# HT32F52243_53 register map
File version: 1.0
This is the description for the Holtek HT32F52243_53
CPU: CM0+ r0p1, little endian, no MPU, no FPU, 4 interrupt priority bits
Registers are 32-bit, read-write, reset 0x0 unless marked. A register's access mark holds for its fields unless they carry their own. Offsets are from the block's base; lines under a group give offsets from that group; [hi:lo] are bit positions; {n}, {i} and the like mark numbered series; 'fields as' and 'values as' point back to an identical list; <NAME> marks a mode.

## Memory map
0xE000E000 NVIC size 0x1000

## NVIC
Base 0xE000E000
0x04 ICTR
  [4:0] INTLINESNUM
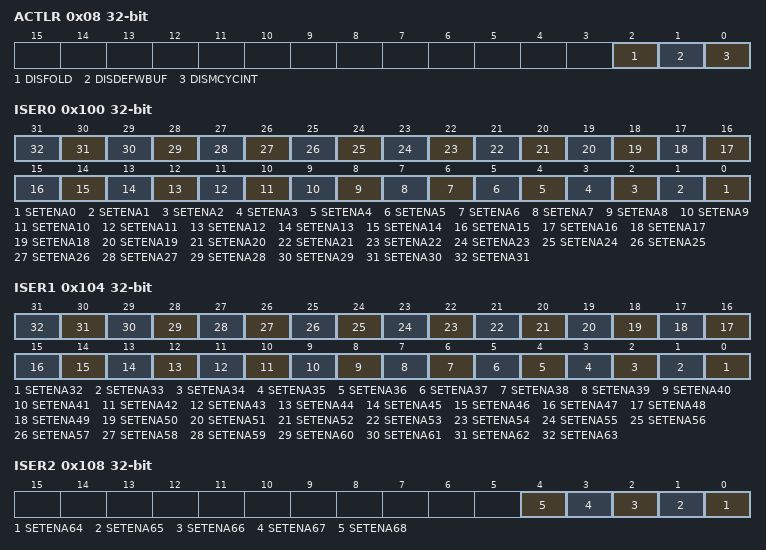
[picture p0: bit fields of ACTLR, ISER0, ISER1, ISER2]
0x08 ACTLR
  [2] DISFOLD, [1] DISDEFWBUF, [0] DISMCYCINT
0x100 ISER0
  [n] SETENA{n} (n=0..31)
0x104 ISER1
  [n-32] SETENA{n} (n=32..63)
0x108 ISER2
  [n-64] SETENA{n} (n=64..68)
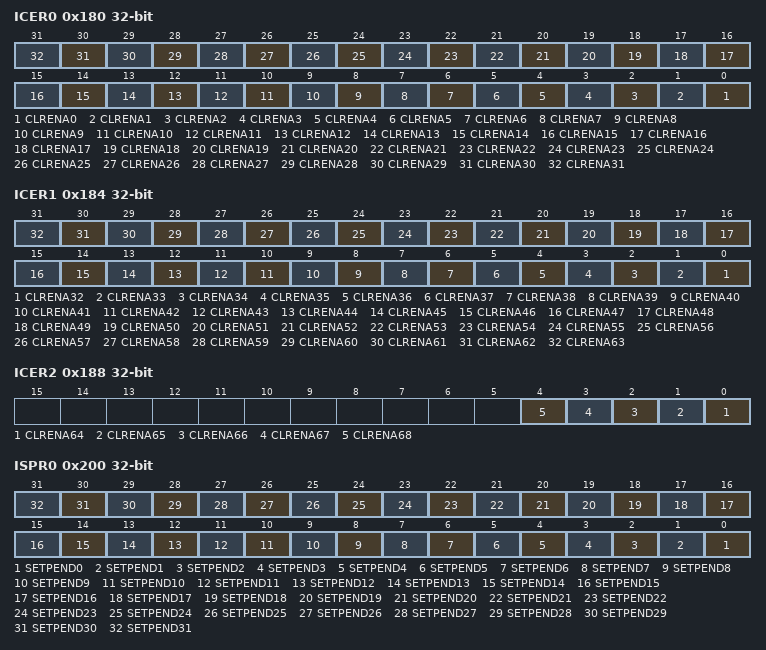
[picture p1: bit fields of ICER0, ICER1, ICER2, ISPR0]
0x180 ICER0
  [n] CLRENA{n} (n=0..31)
0x184 ICER1
  [n-32] CLRENA{n} (n=32..63)
0x188 ICER2
  [n-64] CLRENA{n} (n=64..68)
0x200 ISPR0
  [n] SETPEND{n} (n=0..31)
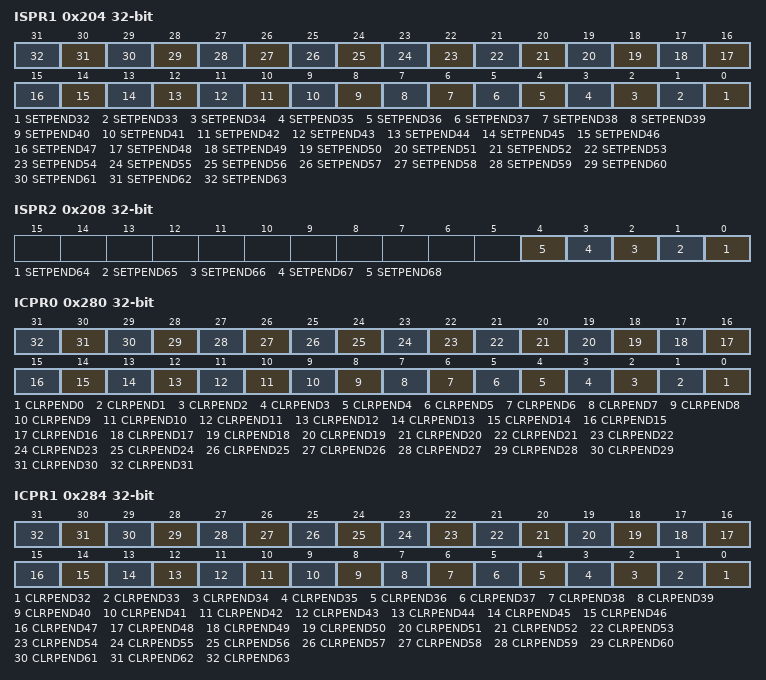
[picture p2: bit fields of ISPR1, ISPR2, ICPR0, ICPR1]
0x204 ISPR1
  [n-32] SETPEND{n} (n=32..63)
0x208 ISPR2
  [n-64] SETPEND{n} (n=64..68)
0x280 ICPR0
  [n] CLRPEND{n} (n=0..31)
0x284 ICPR1
  [n-32] CLRPEND{n} (n=32..63)
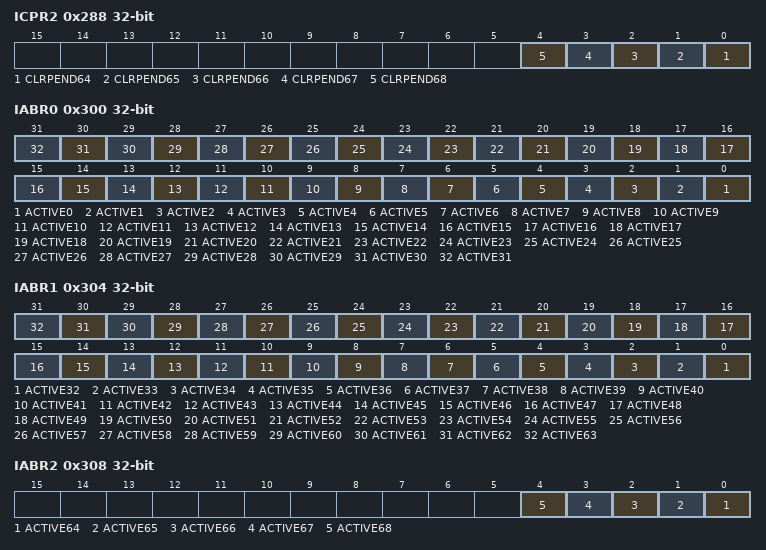
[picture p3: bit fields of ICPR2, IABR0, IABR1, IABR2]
0x288 ICPR2
  [n-64] CLRPEND{n} (n=64..68)
0x300 IABR0
  [n] ACTIVE{n} (n=0..31)
0x304 IABR1
  [n-32] ACTIVE{n} (n=32..63)
0x308 IABR2
  [n-64] ACTIVE{n} (n=64..68)
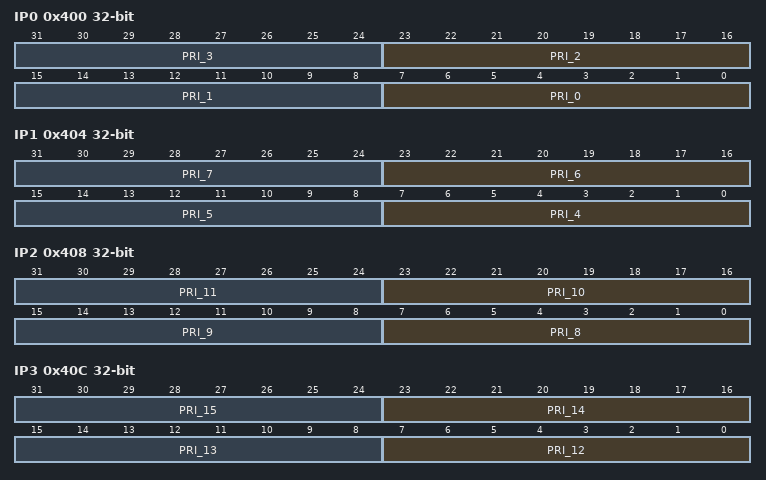
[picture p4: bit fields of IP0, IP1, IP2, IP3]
0x400 IP0
  [8n+7:8n] PRI_{n} (n=0..3)
0x404 IP1
  [8n-25:8n-32] PRI_{n} (n=4..7)
0x408 IP2
  [8n-57:8n-64] PRI_{n} (n=8..11)
0x40C IP3
  [8n-89:8n-96] PRI_{n} (n=12..15)
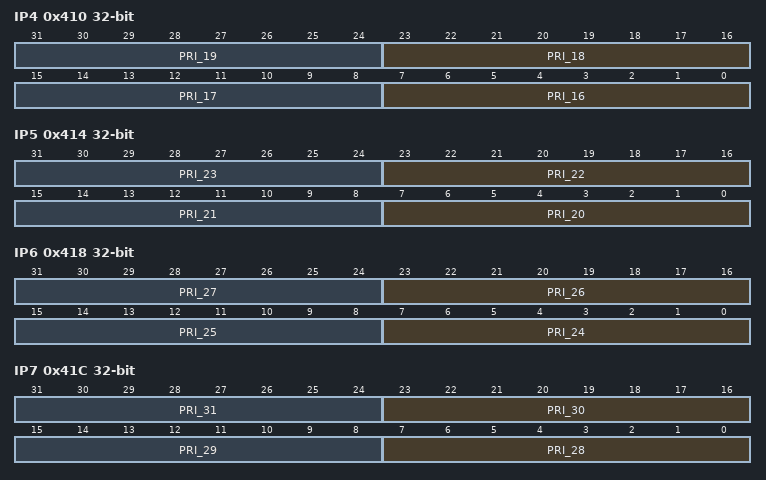
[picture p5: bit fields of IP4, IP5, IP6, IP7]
0x410 IP4
  [8n-121:8n-128] PRI_{n} (n=16..19)
0x414 IP5
  [8n-153:8n-160] PRI_{n} (n=20..23)
0x418 IP6
  [8n-185:8n-192] PRI_{n} (n=24..27)
0x41C IP7
  [8n-217:8n-224] PRI_{n} (n=28..31)
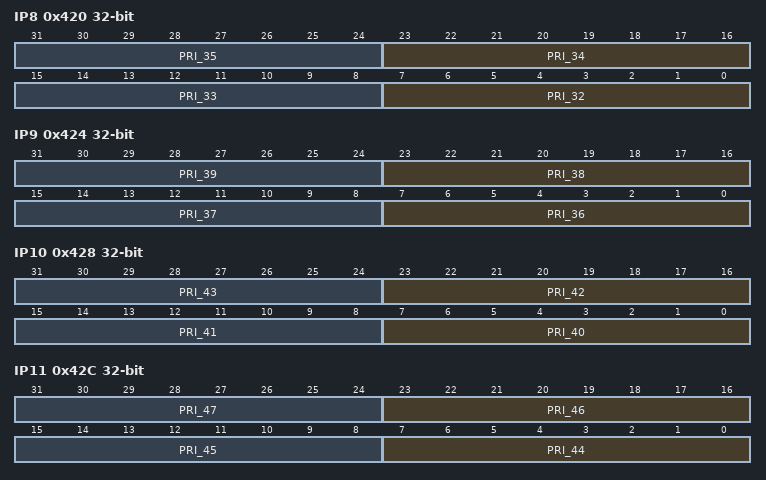
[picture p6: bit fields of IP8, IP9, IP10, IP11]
0x420 IP8
  [8n-249:8n-256] PRI_{n} (n=32..35)
0x424 IP9
  [8n-281:8n-288] PRI_{n} (n=36..39)
0x428 IP10
  [8n-313:8n-320] PRI_{n} (n=40..43)
0x42C IP11
  [8n-345:8n-352] PRI_{n} (n=44..47)
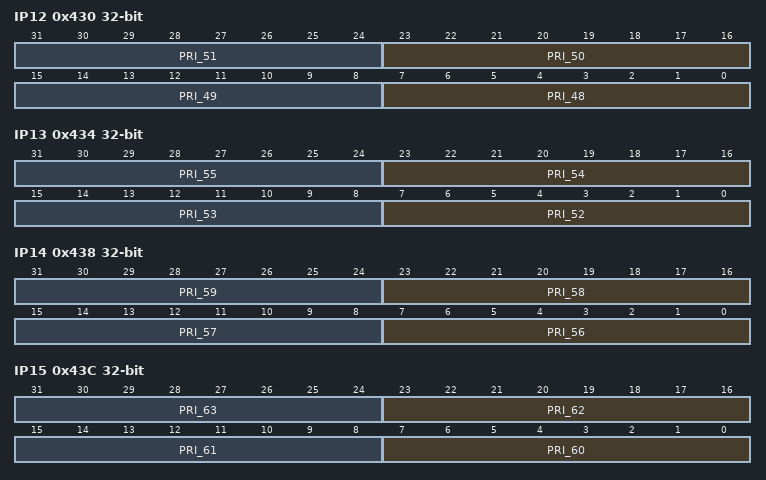
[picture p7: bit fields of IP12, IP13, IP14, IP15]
0x430 IP12
  [8n-377:8n-384] PRI_{n} (n=48..51)
0x434 IP13
  [8n-409:8n-416] PRI_{n} (n=52..55)
0x438 IP14
  [8n-441:8n-448] PRI_{n} (n=56..59)
0x43C IP15
  [8n-473:8n-480] PRI_{n} (n=60..63)
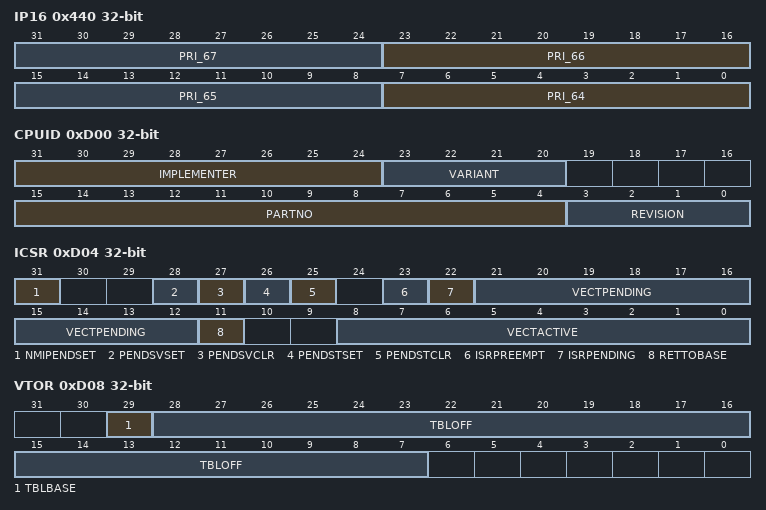
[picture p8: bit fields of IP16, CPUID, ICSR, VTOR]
0x440 IP16
  [8n-505:8n-512] PRI_{n} (n=64..67)
0x444 IP17
  [7:0] PRI_68
0xD00 CPUID
  [31:24] IMPLEMENTER, [23:20] VARIANT, [15:4] PARTNO, [3:0] REVISION
0xD04 ICSR
  [31] NMIPENDSET, [28] PENDSVSET, [27] PENDSVCLR, [26] PENDSTSET, [25] PENDSTCLR, [23] ISRPREEMPT, [22] ISRPENDING, [21:12] VECTPENDING, [11] RETTOBASE, [8:0] VECTACTIVE
0xD08 VTOR
  [29] TBLBASE, [28:7] TBLOFF
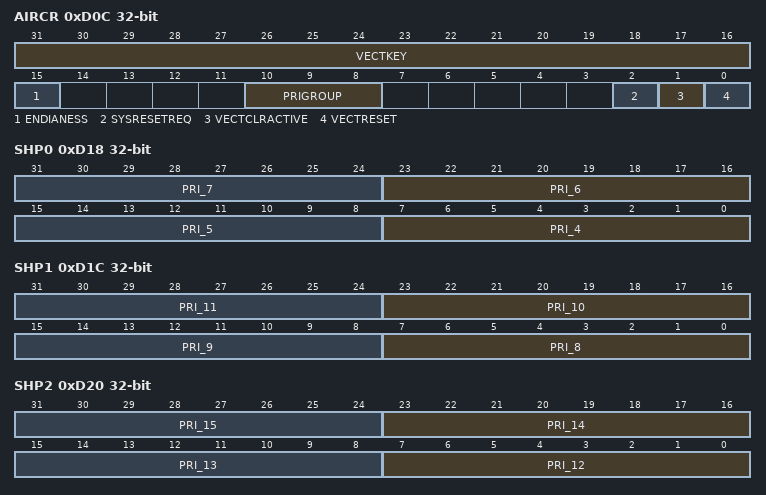
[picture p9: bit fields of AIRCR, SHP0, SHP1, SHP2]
0xD0C AIRCR
  [31:16] VECTKEY, [15] ENDIANESS, [10:8] PRIGROUP, [2] SYSRESETREQ, [1] VECTCLRACTIVE, [0] VECTRESET
0xD18 SHP0
  [8n-25:8n-32] PRI_{n} (n=4..7)
0xD1C SHP1
  [8n-57:8n-64] PRI_{n} (n=8..11)
0xD20 SHP2
  [8n-89:8n-96] PRI_{n} (n=12..15)
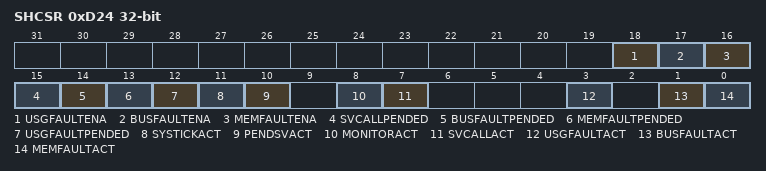
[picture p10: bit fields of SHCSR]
0xD24 SHCSR
  [18] USGFAULTENA, [17] BUSFAULTENA, [16] MEMFAULTENA, [15] SVCALLPENDED, [14] BUSFAULTPENDED, [13] MEMFAULTPENDED, [12] USGFAULTPENDED, [11] SYSTICKACT, [10] PENDSVACT, [8] MONITORACT, [7] SVCALLACT, [3] USGFAULTACT, [1] BUSFAULTACT, [0] MEMFAULTACT
0xF00 STIR
  [8:0] INTID

## Notices in the file
Copyright (C) 2010 ARM Limited. All rights reserved.
ARM Limited (ARM) is supplying this SVD description for use with Cortex-M3
processor based microcontrollers.  This file and or content can be freely
distributed within development tools that are supporting such ARM based
processors.
THIS SOFTWARE IS PROVIDED "AS IS".  NO WARRANTIES, WHETHER EXPRESS, IMPLIED
OR STATUTORY, INCLUDING, BUT NOT LIMITED TO, IMPLIED WARRANTIES OF
MERCHANTABILITY AND FITNESS FOR A PARTICULAR PURPOSE APPLY TO THIS SOFTWARE.
ARM SHALL NOT, IN ANY CIRCUMSTANCES, BE LIABLE FOR SPECIAL, INCIDENTAL, OR
CONSEQUENTIAL DAMAGES, FOR ANY REASON WHATSOEVER.
